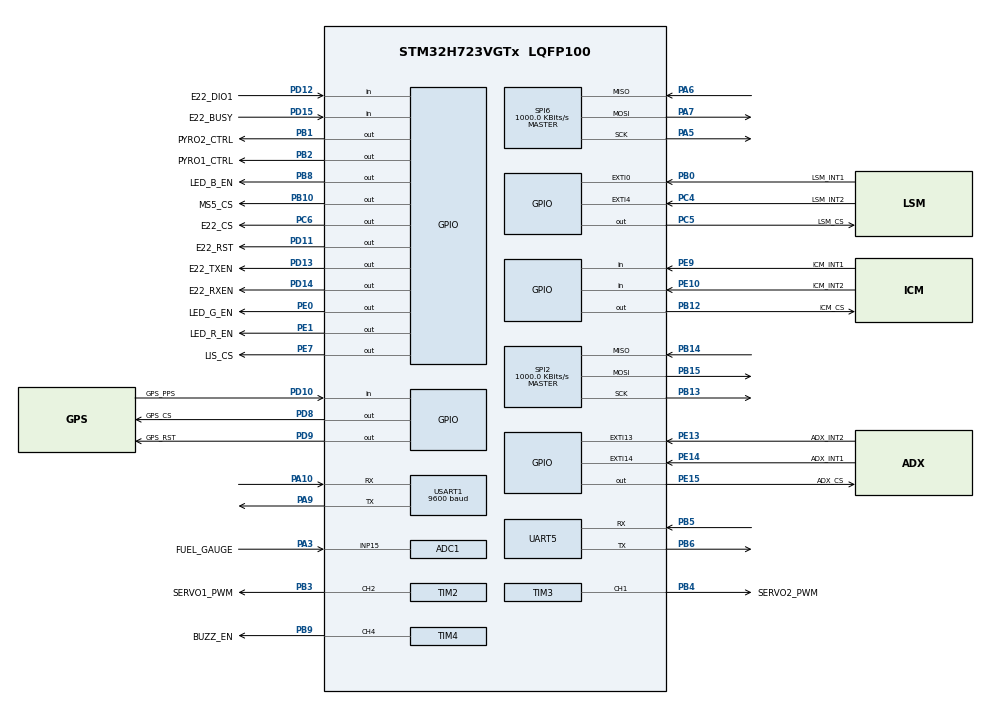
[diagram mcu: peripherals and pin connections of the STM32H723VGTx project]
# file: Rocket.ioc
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ADC1.Channel-4\#ChannelRegularConversion=ADC_CHANNEL_15
ADC1.NbrOfConversionFlag=1
ADC1.OffsetNumber-4\#ChannelRegularConversion=ADC_OFFSET_NONE
ADC1.OffsetSignedSaturation-4\#ChannelRegularConversion=DISABLE
ADC1.Rank-4\#ChannelRegularConversion=1
ADC1.SamplingTime-4\#ChannelRegularConversion=ADC_SAMPLETIME_1CYCLE_5
ADC1.master=1
CORTEX_M7.Enable_Spec=__NULL
CORTEX_M7.MPU_Control=__NULL
CORTEX_M7.default_mode_Activation=1
Mcu.Family=STM32H7
Mcu.Name=STM32H723VGTx
Mcu.Package=LQFP100
NVIC.PriorityGroup=NVIC_PRIORITYGROUP_4
NVIC.USART1_IRQn=true\:0\:0\:false\:false\:true\:true\:true\:true
PA10.Mode=Asynchronous
PA10.Signal=USART1_RX
PA13(JTMS/SWDIO).Mode=Serial_Wire
PA13(JTMS/SWDIO).Signal=DEBUG_JTMS-SWDIO
PA14(JTCK/SWCLK).Mode=Serial_Wire
PA14(JTCK/SWCLK).Signal=DEBUG_JTCK-SWCLK
PA3.GPIO_Label=FUEL_GAUGE
PA3.Signal=ADCx_INP15
PA5.Mode=Full_Duplex_Master
PA5.Signal=SPI6_SCK
PA6.Mode=Full_Duplex_Master
PA6.Signal=SPI6_MISO
PA7.Mode=Full_Duplex_Master
PA7.Signal=SPI6_MOSI
PA9.Mode=Asynchronous
PA9.Signal=USART1_TX
PB0.GPIO_Label=LSM_INT1
PB0.Signal=GPXTI0
PB1.GPIO_Label=PYRO2_CTRL
PB1.Signal=GPIO_Output
PB10.GPIO_Label=MS5_CS
PB10.GPIO_ModeDefaultOutputPP=GPIO_MODE_OUTPUT_PP
PB10.GPIO_PuPd=GPIO_NOPULL
PB10.GPIO_Speed=GPIO_SPEED_FREQ_HIGH
PB10.PinState=GPIO_PIN_SET
PB10.Signal=GPIO_Output
PB12.GPIO_Label=ICM_CS
PB12.GPIO_Speed=GPIO_SPEED_FREQ_HIGH
PB12.PinState=GPIO_PIN_SET
PB12.Signal=GPIO_Output
PB13.Mode=Full_Duplex_Master
PB13.Signal=SPI2_SCK
PB14.Mode=Full_Duplex_Master
PB14.Signal=SPI2_MISO
PB15.Mode=Full_Duplex_Master
PB15.Signal=SPI2_MOSI
PB2.GPIO_Label=PYRO1_CTRL
PB2.Signal=GPIO_Output
PB3(JTDO/TRACESWO).GPIO_Label=SERVO1_PWM
PB3(JTDO/TRACESWO).Signal=S_TIM2_CH2
PB4(NJTRST).GPIO_Label=SERVO2_PWM
PB4(NJTRST).Signal=S_TIM3_CH1
PB5.Mode=Asynchronous
PB5.Signal=UART5_RX
PB6.Mode=Asynchronous
PB6.Signal=UART5_TX
PB8.GPIO_Label=LED_B_EN
PB8.Signal=GPIO_Output
PB9.GPIO_Label=BUZZ_EN
PB9.Signal=S_TIM4_CH4
PC10.Signal=SDMMC1_D2
PC11.Signal=SDMMC1_D3
PC12.Signal=SDMMC1_CK
PC4.GPIO_Label=LSM_INT2
PC4.Signal=GPXTI4
PC5.GPIO_Label=LSM_CS
PC5.GPIO_Speed=GPIO_SPEED_FREQ_HIGH
PC5.PinState=GPIO_PIN_SET
PC5.Signal=GPIO_Output
PC6.GPIO_Label=E22_CS
PC6.GPIO_Speed=GPIO_SPEED_FREQ_HIGH
PC6.PinState=GPIO_PIN_SET
PC6.Signal=GPIO_Output
PC8.Signal=SDMMC1_D0
PC9.Signal=SDMMC1_D1
PD10.GPIO_Label=GPS_PPS
PD10.Signal=GPIO_Input
PD11.GPIO_Label=E22_RST
PD11.GPIO_Speed=GPIO_SPEED_FREQ_HIGH
PD11.PinState=GPIO_PIN_SET
PD11.Signal=GPIO_Output
PD12.GPIO_Label=E22_DIO1
PD12.Signal=GPIO_Input
PD13.GPIO_Label=E22_TXEN
PD13.GPIO_Speed=GPIO_SPEED_FREQ_HIGH
PD13.Signal=GPIO_Output
PD14.GPIO_Label=E22_RXEN
PD14.GPIO_Speed=GPIO_SPEED_FREQ_HIGH
PD14.Signal=GPIO_Output
PD15.GPIO_Label=E22_BUSY
PD15.GPIO_Mode=GPIO_MODE_INPUT
PD15.Signal=GPIO_Input
PD2.Signal=SDMMC1_CMD
PD8.GPIO_Label=GPS_CS
PD8.GPIO_Speed=GPIO_SPEED_FREQ_HIGH
PD8.PinState=GPIO_PIN_SET
PD8.Signal=GPIO_Output
PD9.GPIO_Label=GPS_RST
PD9.GPIO_Speed=GPIO_SPEED_FREQ_LOW
PD9.PinState=GPIO_PIN_SET
PD9.Signal=GPIO_Output
PE0.GPIO_Label=LED_G_EN
PE0.Signal=GPIO_Output
PE1.GPIO_Label=LED_R_EN
PE1.Signal=GPIO_Output
PE10.GPIO_Label=ICM_INT2
PE10.Signal=GPIO_Input
PE13.GPIO_Label=ADX_INT2
PE13.Signal=GPXTI13
PE14.GPIO_Label=ADX_INT1 
PE14.Signal=GPXTI14
PE15.GPIO_Label=ADX_CS
PE15.GPIO_Speed=GPIO_SPEED_FREQ_HIGH
PE15.PinState=GPIO_PIN_SET
PE15.Signal=GPIO_Output
PE7.GPIO_Label=LIS_CS
PE7.GPIO_Speed=GPIO_SPEED_FREQ_HIGH
PE7.PinState=GPIO_PIN_SET
PE7.Signal=GPIO_Output
PE9.GPIO_Label=ICM_INT1
PE9.Signal=GPIO_Input
PH0-OSC_IN.Mode=HSE-External-Oscillator
PH0-OSC_IN.Signal=RCC_OSC_IN
PH1-OSC_OUT.Mode=HSE-External-Oscillator
PH1-OSC_OUT.Signal=RCC_OSC_OUT
ProjectManager.HeapSize=0x200
ProjectManager.StackSize=0x400
ProjectManager.TargetToolchain=CMake
RCC.ADCFreq_Value=38400000
RCC.APB1Freq_Value=32000000
RCC.APB2Freq_Value=32000000
RCC.APB3Freq_Value=64000000
RCC.APB4Freq_Value=64000000
RCC.CortexFreq_Value=64000000
RCC.D2PPRE1=RCC_APB1_DIV2
RCC.D2PPRE2=RCC_APB2_DIV2
RCC.DIVM1=4
RCC.DIVM2=4
RCC.DIVN1=12
RCC.DIVN2=12
RCC.DIVP2=5
RCC.DIVQ1=3
RCC.HCLKFreq_Value=64000000
RCC.PLL2FRACN=0
RCC.PLL3FRACN=0
RCC.PLLFRACN=0
RCC.SYSCLKFreq_VALUE=64000000
RCC.USBFreq_Value=64000000
SH.ADCx_INP15.0=ADC1_INP15,IN15-Single-Ended
SH.S_TIM2_CH2.0=TIM2_CH2,PWM Generation2 CH2
SH.S_TIM3_CH1.0=TIM3_CH1,PWM Generation1 CH1
SH.S_TIM4_CH4.0=TIM4_CH4,PWM Generation4 CH4
SPI2.BaudRatePrescaler=SPI_BAUDRATEPRESCALER_64
SPI2.CLKPhase=SPI_PHASE_2EDGE
SPI2.CLKPolarity=SPI_POLARITY_HIGH
SPI2.CalculateBaudRate=1000.0 KBits/s
SPI2.DataSize=SPI_DATASIZE_8BIT
SPI2.Direction=SPI_DIRECTION_2LINES
SPI2.Mode=SPI_MODE_MASTER
SPI2.VirtualType=VM_MASTER
SPI6.BaudRatePrescaler=SPI_BAUDRATEPRESCALER_64
SPI6.CLKPhase=SPI_PHASE_1EDGE
SPI6.CLKPolarity=SPI_POLARITY_LOW
SPI6.CalculateBaudRate=1000.0 KBits/s
SPI6.DataSize=SPI_DATASIZE_8BIT
SPI6.Direction=SPI_DIRECTION_2LINES
SPI6.Mode=SPI_MODE_MASTER
SPI6.VirtualType=VM_MASTER
TIM2.Channel-PWM\ Generation2\ CH2=TIM_CHANNEL_2
TIM3.Channel-PWM\ Generation1\ CH1=TIM_CHANNEL_1
TIM4.Channel-PWM\ Generation4\ CH4=TIM_CHANNEL_4
USART1.BaudRate=9600
USART1.VirtualMode-Asynchronous=VM_ASYNC
VP_MEMORYMAP_VS_MEMORYMAP.Mode=CurAppReg
board=custom

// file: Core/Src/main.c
/* USER CODE BEGIN Header */
/**
 ******************************************************************************
 * @file           : main.c
 * @brief          : Main program body
 ******************************************************************************
 * @attention
 *
 * Copyright (c) 2025 STMicroelectronics.
 * All rights reserved.
 *
 * This software is licensed under terms that can be found in the LICENSE file
 * in the root directory of this software component.
 * If no LICENSE file comes with this software, it is provided AS-IS.
 *
 ******************************************************************************
 */
/* USER CODE END Header */
#include "main.h"
#include "adc.h"
#include "spi.h"
#include "tim.h"
#include "usart.h"
#include "gpio.h"

/* USER CODE BEGIN Includes */
#include "user_main.h"
/* USER CODE END Includes */

void SystemClock_Config(void);

int main(void)
{

  /* MCU Configuration--------------------------------------------------------*/

  /* Reset of all peripherals, Initializes the Flash interface and the Systick. */
  HAL_Init();

  /* Configure the system clock */
  SystemClock_Config();

  /* Initialize all configured peripherals */
  MX_GPIO_Init();
  MX_SPI2_Init();
  MX_SPI6_Init();
  MX_UART5_Init();
  MX_TIM2_Init();
  MX_TIM3_Init();
  MX_TIM4_Init();
  MX_ADC1_Init();
  MX_USART1_UART_Init();
  /* USER CODE BEGIN 2 */
  // Entry point for user code
  /*ENTRY POINT FOR RAY FIRMWARE*/
  user_main();
  /* USER CODE END 2 */

  /* Infinite loop */
  while (1)
  {

  }
}

void SystemClock_Config(void)
{
  RCC_OscInitTypeDef RCC_OscInitStruct = {0};
  RCC_ClkInitTypeDef RCC_ClkInitStruct = {0};

  /** Supply configuration update enable
   */
  HAL_PWREx_ConfigSupply(PWR_LDO_SUPPLY);

  /** Configure the main internal regulator output voltage
   */
  __HAL_PWR_VOLTAGESCALING_CONFIG(PWR_REGULATOR_VOLTAGE_SCALE3);

  while (!__HAL_PWR_GET_FLAG(PWR_FLAG_VOSRDY))
  {
  }

  /** Initializes the RCC Oscillators according to the specified parameters
   * in the RCC_OscInitTypeDef structure.
   */
  RCC_OscInitStruct.OscillatorType = RCC_OSCILLATORTYPE_HSI;
  RCC_OscInitStruct.HSIState = RCC_HSI_DIV1;
  RCC_OscInitStruct.HSICalibrationValue = 64;
  RCC_OscInitStruct.PLL.PLLState = RCC_PLL_ON;
  RCC_OscInitStruct.PLL.PLLSource = RCC_PLLSOURCE_HSI;
  RCC_OscInitStruct.PLL.PLLM = 4;
  RCC_OscInitStruct.PLL.PLLN = 12;
  RCC_OscInitStruct.PLL.PLLP = 2;
  RCC_OscInitStruct.PLL.PLLQ = 3;
  RCC_OscInitStruct.PLL.PLLR = 2;
  RCC_OscInitStruct.PLL.PLLRGE = RCC_PLL1VCIRANGE_3;
  RCC_OscInitStruct.PLL.PLLVCOSEL = RCC_PLL1VCOWIDE;
  RCC_OscInitStruct.PLL.PLLFRACN = 0;
  if (HAL_RCC_OscConfig(&RCC_OscInitStruct) != HAL_OK)
  {
    Error_Handler();
  }

  /** Initializes the CPU, AHB and APB buses clocks
   */
  RCC_ClkInitStruct.ClockType = RCC_CLOCKTYPE_HCLK | RCC_CLOCKTYPE_SYSCLK | RCC_CLOCKTYPE_PCLK1 | RCC_CLOCKTYPE_PCLK2 | RCC_CLOCKTYPE_D3PCLK1 | RCC_CLOCKTYPE_D1PCLK1;
  RCC_ClkInitStruct.SYSCLKSource = RCC_SYSCLKSOURCE_HSI;
  RCC_ClkInitStruct.SYSCLKDivider = RCC_SYSCLK_DIV1;
  RCC_ClkInitStruct.AHBCLKDivider = RCC_HCLK_DIV1;
  RCC_ClkInitStruct.APB3CLKDivider = RCC_APB3_DIV1;
  RCC_ClkInitStruct.APB1CLKDivider = RCC_APB1_DIV2;
  RCC_ClkInitStruct.APB2CLKDivider = RCC_APB2_DIV2;
  RCC_ClkInitStruct.APB4CLKDivider = RCC_APB4_DIV1;

  if (HAL_RCC_ClockConfig(&RCC_ClkInitStruct, FLASH_LATENCY_1) != HAL_OK)
  {
    Error_Handler();
  }
}

void Error_Handler(void)
{
  __disable_irq();
  while (1)
  {
  }
}
